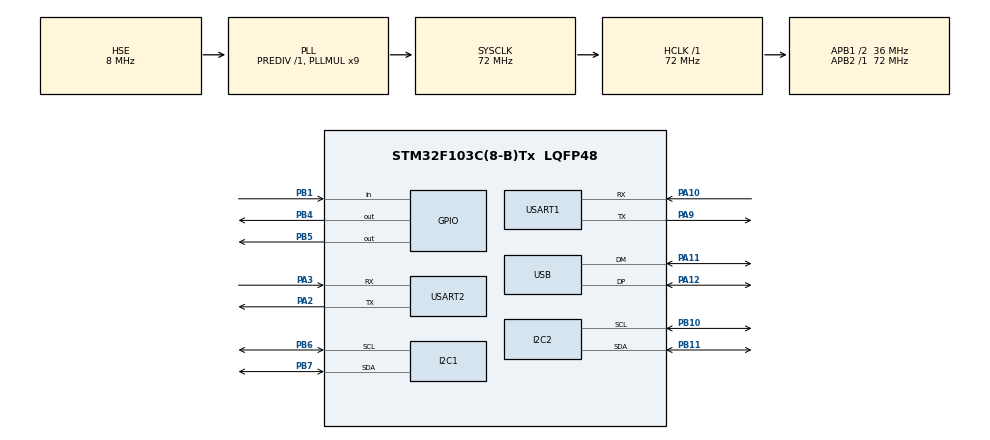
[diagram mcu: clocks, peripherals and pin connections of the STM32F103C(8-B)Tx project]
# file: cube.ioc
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FREERTOS.Tasks01=Oled,24,128,StartOled,Default,NULL,Dynamic,NULL,NULL;Max,8,128,StartMax,Default,NULL,Dynamic,NULL,NULL
I2C1.I2C_Mode=I2C_Fast
Mcu.Family=STM32F1
Mcu.Name=STM32F103C(8-B)Tx
Mcu.Package=LQFP48
NVIC.PriorityGroup=NVIC_PRIORITYGROUP_4
NVIC.TIM1_UP_IRQn=true\:15\:0\:false\:false\:true\:false\:false\:true\:true
NVIC.TimeBase=TIM1_UP_IRQn
NVIC.TimeBaseIP=TIM1
NVIC.USB_LP_CAN1_RX0_IRQn=true\:5\:0\:false\:false\:true\:true\:false\:true\:true
PA10.Mode=Asynchronous
PA10.Signal=USART1_RX
PA11.Mode=Device
PA11.Signal=USB_DM
PA12.Mode=Device
PA12.Signal=USB_DP
PA13.Mode=Serial_Wire
PA13.Signal=SYS_JTMS-SWDIO
PA14.Mode=Serial_Wire
PA14.Signal=SYS_JTCK-SWCLK
PA2.Mode=Asynchronous
PA2.Signal=USART2_TX
PA3.Mode=Asynchronous
PA3.Signal=USART2_RX
PA9.Mode=Asynchronous
PA9.Signal=USART1_TX
PB1.GPIO_PuPd=GPIO_PULLUP
PB1.Signal=GPIO_Input
PB10.Mode=I2C
PB10.Signal=I2C2_SCL
PB11.Mode=I2C
PB11.Signal=I2C2_SDA
PB4.PinState=GPIO_PIN_RESET
PB4.Signal=GPIO_Output
PB5.PinState=GPIO_PIN_SET
PB5.Signal=GPIO_Output
PB6.Mode=I2C
PB6.Signal=I2C1_SCL
PB7.Mode=I2C
PB7.Signal=I2C1_SDA
PD0-OSC_IN.Mode=HSE-External-Oscillator
PD0-OSC_IN.Signal=RCC_OSC_IN
PD1-OSC_OUT.Mode=HSE-External-Oscillator
PD1-OSC_OUT.Signal=RCC_OSC_OUT
ProjectManager.HeapSize=0x300
ProjectManager.StackSize=0x400
ProjectManager.TargetToolchain=Makefile
RCC.AHBFreq_Value=72000000
RCC.APB1CLKDivider=RCC_HCLK_DIV2
RCC.APB1Freq_Value=36000000
RCC.APB1TimFreq_Value=72000000
RCC.APB2Freq_Value=72000000
RCC.APB2TimFreq_Value=72000000
RCC.HCLKFreq_Value=72000000
RCC.PLLMUL=RCC_PLL_MUL9
RCC.PLLSourceVirtual=RCC_PLLSOURCE_HSE
RCC.SYSCLKFreq_VALUE=72000000
RCC.SYSCLKSource=RCC_SYSCLKSOURCE_PLLCLK
RCC.USBFreq_Value=48000000
RCC.USBPrescaler=RCC_USBCLKSOURCE_PLL_DIV1_5
USART1.VirtualMode=VM_ASYNC
USART2.VirtualMode=VM_ASYNC
USB_DEVICE.CLASS_NAME_FS=CDC
USB_DEVICE.VirtualMode=Cdc
USB_DEVICE.VirtualModeFS=Cdc_FS
VP_FREERTOS_VS_CMSIS_V2.Mode=CMSIS_V2
VP_SYS_VS_tim1.Mode=TIM1
VP_USB_DEVICE_VS_USB_DEVICE_CDC_FS.Mode=CDC_FS
board=custom

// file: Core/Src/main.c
/* USER CODE BEGIN Header */
/**
  ******************************************************************************
  * @file           : main.c
  * @brief          : Main program body
  ******************************************************************************
  * @attention
  *
  * Copyright (c) 2024 STMicroelectronics.
  * All rights reserved.
  *
  * This software is licensed under terms that can be found in the LICENSE file
  * in the root directory of this software component.
  * If no LICENSE file comes with this software, it is provided AS-IS.
  *
  ******************************************************************************
  */
/* USER CODE END Header */
#include "main.h"
#include "cmsis_os.h"
#include "i2c.h"
#include "usart.h"
#include "usb_device.h"
#include "gpio.h"

/* USER CODE BEGIN Includes */
#include "oled.h"
#include "Max30102.h"

/* USER CODE END Includes */

void SystemClock_Config(void);
void MX_FREERTOS_Init(void);

int main(void)
{

  /* MCU Configuration--------------------------------------------------------*/

  /* Reset of all peripherals, Initializes the Flash interface and the Systick. */
  HAL_Init();

  /* Configure the system clock */
  SystemClock_Config();

  /* Initialize all configured peripherals */
  MX_GPIO_Init();
  MX_I2C1_Init();
  MX_I2C2_Init();
  MX_USART1_UART_Init();
  MX_USART2_UART_Init();
  /* USER CODE BEGIN 2 */

  OLED_Init();
  Max30102_Init();
  /* USER CODE END 2 */

  /* Init scheduler */
  osKernelInitialize();

  /* Call init function for freertos objects (in cmsis_os2.c) */
  MX_FREERTOS_Init();

  /* Start scheduler */
  osKernelStart();

  /* We should never get here as control is now taken by the scheduler */

  /* Infinite loop */
  while (1)
  {

  }
}

void SystemClock_Config(void)
{
  RCC_OscInitTypeDef RCC_OscInitStruct = {0};
  RCC_ClkInitTypeDef RCC_ClkInitStruct = {0};
  RCC_PeriphCLKInitTypeDef PeriphClkInit = {0};

  /** Initializes the RCC Oscillators according to the specified parameters
  * in the RCC_OscInitTypeDef structure.
  */
  RCC_OscInitStruct.OscillatorType = RCC_OSCILLATORTYPE_HSE;
  RCC_OscInitStruct.HSEState = RCC_HSE_ON;
  RCC_OscInitStruct.HSEPredivValue = RCC_HSE_PREDIV_DIV1;
  RCC_OscInitStruct.HSIState = RCC_HSI_ON;
  RCC_OscInitStruct.PLL.PLLState = RCC_PLL_ON;
  RCC_OscInitStruct.PLL.PLLSource = RCC_PLLSOURCE_HSE;
  RCC_OscInitStruct.PLL.PLLMUL = RCC_PLL_MUL9;
  if (HAL_RCC_OscConfig(&RCC_OscInitStruct) != HAL_OK)
  {
    Error_Handler();
  }

  /** Initializes the CPU, AHB and APB buses clocks
  */
  RCC_ClkInitStruct.ClockType = RCC_CLOCKTYPE_HCLK|RCC_CLOCKTYPE_SYSCLK
                              |RCC_CLOCKTYPE_PCLK1|RCC_CLOCKTYPE_PCLK2;
  RCC_ClkInitStruct.SYSCLKSource = RCC_SYSCLKSOURCE_PLLCLK;
  RCC_ClkInitStruct.AHBCLKDivider = RCC_SYSCLK_DIV1;
  RCC_ClkInitStruct.APB1CLKDivider = RCC_HCLK_DIV2;
  RCC_ClkInitStruct.APB2CLKDivider = RCC_HCLK_DIV1;

  if (HAL_RCC_ClockConfig(&RCC_ClkInitStruct, FLASH_LATENCY_2) != HAL_OK)
  {
    Error_Handler();
  }
  PeriphClkInit.PeriphClockSelection = RCC_PERIPHCLK_USB;
  PeriphClkInit.UsbClockSelection = RCC_USBCLKSOURCE_PLL_DIV1_5;
  if (HAL_RCCEx_PeriphCLKConfig(&PeriphClkInit) != HAL_OK)
  {
    Error_Handler();
  }
}

void HAL_TIM_PeriodElapsedCallback(TIM_HandleTypeDef *htim)
{
  if (htim->Instance == TIM1) {
    HAL_IncTick();
  }
}

void Error_Handler(void)
{
  __disable_irq();
  while (1)
  {
  }
}

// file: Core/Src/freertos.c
/* USER CODE BEGIN Header */
/**
  ******************************************************************************
  * File Name          : freertos.c
  * Description        : Code for freertos applications
  ******************************************************************************
  * @attention
  *
  * Copyright (c) 2024 STMicroelectronics.
  * All rights reserved.
  *
  * This software is licensed under terms that can be found in the LICENSE file
  * in the root directory of this software component.
  * If no LICENSE file comes with this software, it is provided AS-IS.
  *
  ******************************************************************************
  */
/* USER CODE END Header */

#include "FreeRTOS.h"
#include "task.h"
#include "main.h"
#include "cmsis_os.h"

/* USER CODE BEGIN Includes */
#include "oled.h"
#include "Max30102.h"
#include "usb_device.h"
#include "usbd_cdc_if.h"

/* USER CODE END Includes */

/* Definitions for Oled */
osThreadId_t OledHandle;
const osThreadAttr_t Oled_attributes = {
  .name = "Oled",
  .stack_size = 128 * 4,
  .priority = (osPriority_t) osPriorityNormal,
};
/* Definitions for Max */
osThreadId_t MaxHandle;
const osThreadAttr_t Max_attributes = {
  .name = "Max",
  .stack_size = 128 * 4,
  .priority = (osPriority_t) osPriorityLow,
};

void StartOled(void *argument);
void StartMax(void *argument);

extern void MX_USB_DEVICE_Init(void);
void MX_FREERTOS_Init(void); /* (MISRA C 2004 rule 8.1) */

void MX_FREERTOS_Init(void) {

  /* Create the thread(s) */
  /* creation of Oled */
  OledHandle = osThreadNew(StartOled, NULL, &Oled_attributes);

  /* creation of Max */
  MaxHandle = osThreadNew(StartMax, NULL, &Max_attributes);

}

void StartOled(void *argument)
{
  /* init code for USB_DEVICE */
  MX_USB_DEVICE_Init();
  /* USER CODE BEGIN StartOled */
  /* Infinite loop */
  // uint8_t send_data[]="123456\r\n";

  OLED_ShowString(4,1,"jikli");
  Max30102_Safety();

  for(;;)
  {
    // OLED_ShowString(0,0 ,"hello" ,8 );
    // CDC_Transmit_FS(send_data,sizeof(send_data));
    // osDelay(500);
    // OLED_ShowString(10,10 ,"world" ,8 );
 	Read();
    osDelay(200);
  }
  /* USER CODE END StartOled */
}

void StartMax(void *argument)
{
  /* USER CODE BEGIN StartMax */
  /* Infinite loop */
  for(;;)
  {
    // osDelay(200);
    // OLED_ShowString(0,0 ,"world" ,8 );
    // osDelay(500);
    // OLED_ShowString(10,10 ,"hello" ,8 );
  }
  /* USER CODE END StartMax */
}
